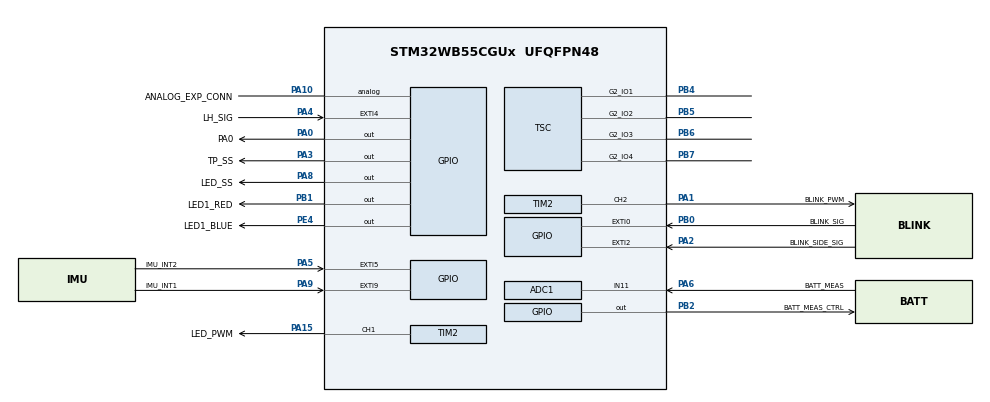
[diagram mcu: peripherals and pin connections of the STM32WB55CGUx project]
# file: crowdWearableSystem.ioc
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ADC1.Channel-0\#ChannelRegularConversion=ADC_CHANNEL_11
ADC1.NbrOfConversionFlag=1
ADC1.OffsetNumber-0\#ChannelRegularConversion=ADC_OFFSET_NONE
ADC1.Rank-0\#ChannelRegularConversion=1
ADC1.SamplingTime-0\#ChannelRegularConversion=ADC_SAMPLETIME_2CYCLES_5
ADC1.master=1
Mcu.Family=STM32WB
Mcu.Name=STM32WB55CGUx
Mcu.Package=UFQFPN48
NVIC.PriorityGroup=NVIC_PRIORITYGROUP_4
NVIC.TSC_IRQn=true\:0\:0\:false\:false\:true\:true\:true
OSC_IN.Mode=HSE-External-Oscillator
OSC_IN.Signal=RCC_OSC_IN
OSC_OUT.Mode=HSE-External-Oscillator
OSC_OUT.Signal=RCC_OSC_OUT
PA0.GPIO_Label=PA0
PA0.Signal=GPIO_Output
PA1.GPIO_Label=BLINK_PWM
PA1.Signal=S_TIM2_CH2
PA10.GPIO_Label=ANALOG_EXP_CONN
PA10.Signal=GPIO_Analog
PA13.Mode=Serial_Wire
PA13.Signal=SYS_JTMS-SWDIO
PA14.Mode=Serial_Wire
PA14.Signal=SYS_JTCK-SWCLK
PA15.GPIO_Label=LED_PWM
PA15.Signal=S_TIM2_CH1
PA2.GPIO_Label=BLINK_SIDE_SIG
PA2.Signal=GPXTI2
PA3.GPIO_Label=TP_SS
PA3.Signal=GPIO_Output
PA4.GPIO_Label=LH_SIG
PA4.Signal=GPXTI4
PA5.GPIO_Label=IMU_INT2
PA5.Signal=GPXTI5
PA6.GPIO_Label=BATT_MEAS
PA6.Signal=ADCx_IN11
PA8.GPIO_Label=LED_SS
PA8.Signal=GPIO_Output
PA9.GPIO_Label=IMU_INT1
PA9.Signal=GPXTI9
PB0.GPIO_Label=BLINK_SIG
PB0.Signal=GPXTI0
PB1.GPIO_Label=LED1_RED
PB1.GPIO_ModeDefaultOutputPP=GPIO_MODE_OUTPUT_OD
PB1.PinState=GPIO_PIN_SET
PB1.Signal=GPIO_Output
PB2.GPIO_Label=BATT_MEAS_CTRL
PB2.GPIO_ModeDefaultOutputPP=GPIO_MODE_OUTPUT_OD
PB2.GPIO_PuPd=GPIO_NOPULL
PB2.PinState=GPIO_PIN_SET
PB2.Signal=GPIO_Output
PB4.Mode=G2_IO1-Sampling
PB4.Signal=TSC_G2_IO1
PB5.Mode=G2_IO2-Channel
PB5.Signal=TSC_G2_IO2
PB6.Mode=G2_IO3-Channel
PB6.Signal=TSC_G2_IO3
PB7.Mode=G2_IO4-Channel
PB7.Signal=TSC_G2_IO4
PC14-OSC32_IN.Mode=LSE-External-Oscillator
PC14-OSC32_IN.Signal=RCC_OSC32_IN
PC15-OSC32_OUT.Mode=LSE-External-Oscillator
PC15-OSC32_OUT.Signal=RCC_OSC32_OUT
PE4.GPIO_Label=LED1_BLUE
PE4.PinState=GPIO_PIN_SET
PE4.Signal=GPIO_Output
ProjectManager.HeapSize=0x200
ProjectManager.StackSize=0x400
ProjectManager.TargetToolchain=TrueSTUDIO
RCC.ADCFreq_Value=48000000
RCC.AHB2CLKDivider=RCC_SYSCLK_DIV2
RCC.AHBFreq_Value=64000000
RCC.APB1Freq_Value=64000000
RCC.APB1TimFreq_Value=64000000
RCC.APB2Freq_Value=64000000
RCC.APB2TimFreq_Value=64000000
RCC.APB3Freq_Value=16000000
RCC.CortexFreq_Value=64000000
RCC.HCLKFreq_Value=64000000
RCC.HSE_VALUE=32000000
RCC.HSI48_VALUE=48000000
RCC.HSI_VALUE=16000000
RCC.LSE_Drive_Capability=RCC_LSEDRIVE_LOW
RCC.MSIAutoCalibration=ENABLED
RCC.PLLN=32
RCC.PLLSAI1N=24
RCC.SMPSCLockSelectionVirtual=RCC_SMPSCLKSOURCE_HSE
RCC.SYSCLKFreq_VALUE=64000000
RCC.SYSCLKSource=RCC_SYSCLKSOURCE_PLLCLK
RCC.USBFreq_Value=48000000
RCC.VCOOutputFreq_Value=128000000
SH.ADCx_IN11.0=ADC1_IN11,IN11-Single-Ended
SH.S_TIM2_CH1.0=TIM2_CH1,PWM Generation1 CH1
SH.S_TIM2_CH2.0=TIM2_CH2,PWM Generation2 CH2
TIM2.Channel-PWM\ Generation1\ CH1=TIM_CHANNEL_1
TIM2.Channel-PWM\ Generation2\ CH2=TIM_CHANNEL_2
TOUCHSENSING.IO_3CH_LIN_M1_B_NBR1_CH1=G2_IO2
TOUCHSENSING.IO_3CH_LIN_M1_B_NBR1_CH2=G2_IO3
TOUCHSENSING.IO_3CH_LIN_M1_B_NBR1_CH3=G2_IO4
TOUCHSENSING.TSLPRM_SENSORS_DATAS=TSLPRM_USE_3CH_LIN_M1_B_NBR1 3 1 1 1 
TOUCHSENSING.TSLPRM_USE_3CH_LIN_M1=1
TOUCHSENSING.TSLPRM_USE_3CH_LIN_M1_B_NBR=1
TSC.CTPulseHighLength=TSC_CTPH_1CYCLE
TSC.CTPulseLowLength=TSC_CTPL_1CYCLE
TSC.ChannelIOs-G2_IO2=TSC_GROUP2_IO2
TSC.ChannelIOs-G2_IO3=TSC_GROUP2_IO3
TSC.ChannelIOs-G2_IO4=TSC_GROUP2_IO4
TSC.MaxCountValue=TSC_MCV_511
TSC.SamplingIOs=TSC_GROUP2_IO1
TSC.SpreadSpectrum=DISABLE
VP_TOUCHSENSING_VS_TOUCHSENSING.Mode=TouchSensing_Enabled
board=custom

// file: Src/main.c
/* USER CODE BEGIN Header */
/**
  ******************************************************************************
  * @file           : main.c
  * @brief          : Main program body
  ******************************************************************************
  * @attention
  *
  * <h2><center>&copy; Copyright (c) 2019 STMicroelectronics.
  * All rights reserved.</center></h2>
  *
  * This software component is licensed by ST under Ultimate Liberty license
  * SLA0044, the "License"; You may not use this file except in compliance with
  * the License. You may obtain a copy of the License at:
  *                             www.st.com/SLA0044
  *
  ******************************************************************************
  */
/* USER CODE END Header */

#include "main.h"
#include "adc.h"
#include "tim.h"
#include "touchsensing.h"
#include "tsc.h"
#include "gpio.h"

void SystemClock_Config(void);

int main(void)
{

  /* MCU Configuration--------------------------------------------------------*/

  /* Reset of all peripherals, Initializes the Flash interface and the Systick. */
  HAL_Init();

  /* Configure the system clock */
  SystemClock_Config();

  /* Initialize all configured peripherals */
  MX_GPIO_Init();
  MX_ADC1_Init();
  MX_TSC_Init();
  MX_TOUCHSENSING_Init();
  MX_TIM2_Init();
  /* USER CODE BEGIN 2 */
//  HAL_GPIO_TogglePin(LED1_BLUE_GPIO_Port, LED1_BLUE_Pin);
  HAL_GPIO_TogglePin(LED1_RED_GPIO_Port, LED1_RED_Pin);

  /* USER CODE END 2 */

  /* Infinite loop */
  /* USER CODE BEGIN WHILE */
//  uint32_t i = 0;
  while (1)
  {
    /* USER CODE END WHILE */

    /* USER CODE BEGIN 3 */
//	  HAL_GPIO_TogglePin(LED1_BLUE_GPIO_Port, LED1_BLUE_Pin);
//	  HAL_Delay(100);
//	  HAL_GPIO_TogglePin(LED1_BLUE_GPIO_Port, LED1_BLUE_Pin);
//	  HAL_Delay(100);
//	  i = 0;
//	  while(i <= 1000000000){
//		  i++;
//	  }
	  HAL_Delay(100);
	  HAL_GPIO_TogglePin(LED1_RED_GPIO_Port, LED1_RED_Pin);

  }
  /* USER CODE END 3 */
}

void SystemClock_Config(void)
{
  RCC_OscInitTypeDef RCC_OscInitStruct = {0};
  RCC_ClkInitTypeDef RCC_ClkInitStruct = {0};
  RCC_PeriphCLKInitTypeDef PeriphClkInitStruct = {0};

  /** Configure LSE Drive Capability
  */
  __HAL_RCC_LSEDRIVE_CONFIG(RCC_LSEDRIVE_LOW);
  /** Configure the main internal regulator output voltage
  */
  __HAL_PWR_VOLTAGESCALING_CONFIG(PWR_REGULATOR_VOLTAGE_SCALE1);
  /** Initializes the CPU, AHB and APB busses clocks
  */
  RCC_OscInitStruct.OscillatorType = RCC_OSCILLATORTYPE_HSI|RCC_OSCILLATORTYPE_HSE
                              |RCC_OSCILLATORTYPE_LSE|RCC_OSCILLATORTYPE_MSI;
  RCC_OscInitStruct.HSEState = RCC_HSE_ON;
  RCC_OscInitStruct.LSEState = RCC_LSE_ON;
  RCC_OscInitStruct.HSIState = RCC_HSI_ON;
  RCC_OscInitStruct.MSIState = RCC_MSI_ON;
  RCC_OscInitStruct.HSICalibrationValue = RCC_HSICALIBRATION_DEFAULT;
  RCC_OscInitStruct.MSICalibrationValue = RCC_MSICALIBRATION_DEFAULT;
  RCC_OscInitStruct.MSIClockRange = RCC_MSIRANGE_6;
  RCC_OscInitStruct.PLL.PLLState = RCC_PLL_ON;
  RCC_OscInitStruct.PLL.PLLSource = RCC_PLLSOURCE_MSI;
  RCC_OscInitStruct.PLL.PLLM = RCC_PLLM_DIV1;
  RCC_OscInitStruct.PLL.PLLN = 32;
  RCC_OscInitStruct.PLL.PLLP = RCC_PLLP_DIV2;
  RCC_OscInitStruct.PLL.PLLR = RCC_PLLR_DIV2;
  RCC_OscInitStruct.PLL.PLLQ = RCC_PLLQ_DIV2;
  if (HAL_RCC_OscConfig(&RCC_OscInitStruct) != HAL_OK)
  {
    Error_Handler();
  }
  /** Configure the SYSCLKSource, HCLK, PCLK1 and PCLK2 clocks dividers
  */
  RCC_ClkInitStruct.ClockType = RCC_CLOCKTYPE_HCLK4|RCC_CLOCKTYPE_HCLK2
                              |RCC_CLOCKTYPE_HCLK|RCC_CLOCKTYPE_SYSCLK
                              |RCC_CLOCKTYPE_PCLK1|RCC_CLOCKTYPE_PCLK2;
  RCC_ClkInitStruct.SYSCLKSource = RCC_SYSCLKSOURCE_PLLCLK;
  RCC_ClkInitStruct.AHBCLKDivider = RCC_SYSCLK_DIV1;
  RCC_ClkInitStruct.APB1CLKDivider = RCC_HCLK_DIV1;
  RCC_ClkInitStruct.APB2CLKDivider = RCC_HCLK_DIV1;
  RCC_ClkInitStruct.AHBCLK2Divider = RCC_SYSCLK_DIV2;
  RCC_ClkInitStruct.AHBCLK4Divider = RCC_SYSCLK_DIV1;

  if (HAL_RCC_ClockConfig(&RCC_ClkInitStruct, FLASH_LATENCY_3) != HAL_OK)
  {
    Error_Handler();
  }
  /** Initializes the peripherals clocks
  */
  PeriphClkInitStruct.PeriphClockSelection = RCC_PERIPHCLK_SMPS|RCC_PERIPHCLK_ADC;
  PeriphClkInitStruct.PLLSAI1.PLLN = 24;
  PeriphClkInitStruct.PLLSAI1.PLLP = RCC_PLLP_DIV2;
  PeriphClkInitStruct.PLLSAI1.PLLQ = RCC_PLLQ_DIV2;
  PeriphClkInitStruct.PLLSAI1.PLLR = RCC_PLLR_DIV2;
  PeriphClkInitStruct.PLLSAI1.PLLSAI1ClockOut = RCC_PLLSAI1_ADCCLK;
  PeriphClkInitStruct.AdcClockSelection = RCC_ADCCLKSOURCE_PLLSAI1;
  PeriphClkInitStruct.SmpsClockSelection = RCC_SMPSCLKSOURCE_HSE;
  PeriphClkInitStruct.SmpsDivSelection = RCC_SMPSCLKDIV_RANGE0;

  if (HAL_RCCEx_PeriphCLKConfig(&PeriphClkInitStruct) != HAL_OK)
  {
    Error_Handler();
  }
  /** Enable MSI Auto calibration
  */
  HAL_RCCEx_EnableMSIPLLMode();
}

void Error_Handler(void)
{
}

/************************ (C) COPYRIGHT STMicroelectronics *****END OF FILE****/
